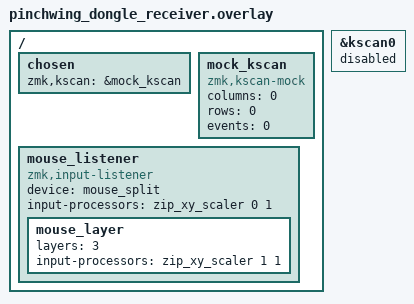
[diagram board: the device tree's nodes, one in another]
/* SPDX-License-Identifier: MIT */
#include "../yellowjacket/yellowjacket.dtsi"
#include "pinchwing-input.dtsi"
#include <input/processors.dtsi>

&kscan0 {
    status = "disabled";
};

/ {
    chosen {
        zmk,kscan = &mock_kscan;
    };

    mock_kscan: mock_kscan {
        compatible = "zmk,kscan-mock";
        columns = <0>;
        rows = <0>;
        events = <0>;
    };

    mouse_listener {
        compatible = "zmk,input-listener";
        device = <&mouse_split>;
        /* Ignore optical motion unless the mouse layer is active. */
        input-processors = <&zip_xy_scaler 0 1>;

        mouse_layer {
            layers = <3>; /* MOUS_L in config/yellowjacket.keymap */
            input-processors = <&zip_xy_scaler 1 1>;
        };
    };
};
